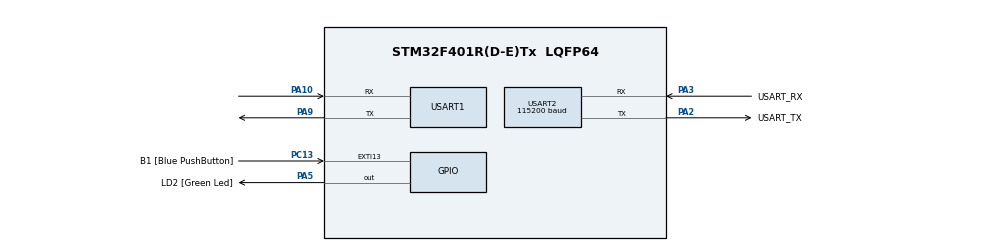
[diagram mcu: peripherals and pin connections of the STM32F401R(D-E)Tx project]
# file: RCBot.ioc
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Mcu.Family=STM32F4
Mcu.Name=STM32F401R(D-E)Tx
Mcu.Package=LQFP64
NVIC.PriorityGroup=NVIC_PRIORITYGROUP_0
PA10.Mode=Asynchronous
PA10.Signal=USART1_RX
PA13.GPIO_Label=TMS
PA13.Mode=Serial_Wire
PA13.Signal=SYS_JTMS-SWDIO
PA14.GPIO_Label=TCK
PA14.Mode=Serial_Wire
PA14.Signal=SYS_JTCK-SWCLK
PA2.GPIO_Label=USART_TX
PA2.GPIO_Mode=GPIO_MODE_AF_PP
PA2.GPIO_PuPd=GPIO_NOPULL
PA2.GPIO_Speed=GPIO_SPEED_FREQ_LOW
PA2.Mode=Asynchronous
PA2.Signal=USART2_TX
PA3.GPIO_Label=USART_RX
PA3.GPIO_Mode=GPIO_MODE_AF_PP
PA3.GPIO_PuPd=GPIO_NOPULL
PA3.GPIO_Speed=GPIO_SPEED_FREQ_LOW
PA3.Mode=Asynchronous
PA3.Signal=USART2_RX
PA5.GPIO_Label=LD2 [Green Led]
PA5.GPIO_Mode=GPIO_MODE_OUTPUT_PP
PA5.GPIO_PuPd=GPIO_NOPULL
PA5.GPIO_Speed=GPIO_SPEED_FREQ_LOW
PA5.Signal=GPIO_Output
PA9.Mode=Asynchronous
PA9.Signal=USART1_TX
PB3.GPIO_Label=SWO
PB3.Signal=SYS_JTDO-SWO
PC13-ANTI_TAMP.GPIO_Label=B1 [Blue PushButton]
PC13-ANTI_TAMP.GPIO_ModeDefaultEXTI=GPIO_MODE_IT_FALLING
PC13-ANTI_TAMP.GPIO_PuPd=GPIO_NOPULL
PC13-ANTI_TAMP.Signal=GPXTI13
PC14-OSC32_IN.Mode=LSE-External-Oscillator
PC14-OSC32_IN.Signal=RCC_OSC32_IN
PC15-OSC32_OUT.Mode=LSE-External-Oscillator
PC15-OSC32_OUT.Signal=RCC_OSC32_OUT
PH0\ -\ OSC_IN.Mode=HSE-External-Clock-Source
PH0\ -\ OSC_IN.Signal=RCC_OSC_IN
PH1\ -\ OSC_OUT.Mode=HSE-External-Clock-Source
PH1\ -\ OSC_OUT.Signal=RCC_OSC_OUT
ProjectManager.HeapSize=0x200
ProjectManager.StackSize=0x400
ProjectManager.TargetToolchain=STM32CubeIDE
RCC.48MHZClocksFreq_Value=48000000
RCC.AHBFreq_Value=84000000
RCC.APB1CLKDivider=RCC_HCLK_DIV2
RCC.APB1Freq_Value=42000000
RCC.APB1TimFreq_Value=84000000
RCC.APB2Freq_Value=84000000
RCC.APB2TimFreq_Value=84000000
RCC.CortexFreq_Value=84000000
RCC.HCLKFreq_Value=84000000
RCC.HSE_VALUE=8000000
RCC.HSI_VALUE=16000000
RCC.PLLN=336
RCC.PLLP=RCC_PLLP_DIV4
RCC.PLLQ=7
RCC.SYSCLKFreq_VALUE=84000000
RCC.SYSCLKSource=RCC_SYSCLKSOURCE_PLLCLK
RCC.VCOOutputFreq_Value=336000000
USART1.VirtualMode=VM_ASYNC
USART2.BaudRate=115200
USART2.VirtualMode=VM_ASYNC
board=NUCLEO-F401RE

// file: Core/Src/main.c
/* USER CODE BEGIN Header */
/**
  ******************************************************************************
  * @file           : main.c
  * @brief          : Main program body
  ******************************************************************************
  */
/* USER CODE END Header */
#include "main.h"
#include <string.h>
#include <stdio.h>

/* USER CODE BEGIN PD */
#define UART_TIMEOUT 1000    // Timeout for LoRa
#define MESSAGE_LENGTH 18    // Length of "Hello from STM32!\r\n"
#define TX_INTERVAL 2000     // 2 seconds between transmissions
#define DEBUG_UART huart2    // Use UART2 for debug messages
/* USER CODE END PD */

UART_HandleTypeDef huart1;
UART_HandleTypeDef huart2;

/* USER CODE BEGIN PV */
uint8_t tx_buffer[] = "Hello from STM32!\r\n";
uint8_t rx_buffer[MESSAGE_LENGTH];
uint32_t last_tx_time = 0;
uint32_t rx_count = 0;
uint32_t tx_count = 0;
uint8_t is_tx_turn = 1;  // Start in TX mode
/* USER CODE END PV */

void SystemClock_Config(void);
static void MX_GPIO_Init(void);
static void MX_USART1_UART_Init(void);
static void MX_USART2_UART_Init(void);

/* USER CODE BEGIN 0 */
void debug_print(const char* msg)
{
    HAL_UART_Transmit(&DEBUG_UART, (uint8_t*)msg, strlen(msg), 100);
}
/* USER CODE END 0 */

int main(void)
{

  /* MCU Configuration--------------------------------------------------------*/

  /* Reset of all peripherals, Initializes the Flash interface and the Systick. */
  HAL_Init();

  /* Configure the system clock */
  SystemClock_Config();

  /* Initialize all configured peripherals */
  MX_GPIO_Init();
  MX_USART1_UART_Init();
  MX_USART2_UART_Init();

  /* USER CODE BEGIN 2 */
  // Initialize LED to OFF state
  HAL_GPIO_WritePin(GPIOA, GPIO_PIN_5, GPIO_PIN_RESET);

  // Store initial time
  last_tx_time = HAL_GetTick();
  /* USER CODE END 2 */

  /* Infinite loop */
  /* USER CODE BEGIN WHILE */
  while (1)
  {
      // Just transmit letter 'A' every second
      uint8_t
{

  huart1.Instance = USART1;
  huart1.Init.BaudRate = 115200;
  huart1.Init.WordLength = UART_WORDLENGTH_8B;
  huart1.Init.StopBits = UART_STOPBITS_1;
  huart1.Init.Parity = UART_PARITY_NONE;
  huart1.Init.Mode = UART_MODE_TX_RX;
  huart1.Init.HwFlowCtl = UART_HWCONTROL_NONE;
  huart1.Init.OverSampling = UART_OVERSAMPLING_16;
  if (HAL_UART_Init(&huart1) != HAL_OK)
  {
    Error_Handler();
  }
}

static void MX_USART2_UART_Init(void)
{

  huart2.Instance = USART2;
  huart2.Init.BaudRate = 115200;
  huart2.Init.WordLength = UART_WORDLENGTH_8B;
  huart2.Init.StopBits = UART_STOPBITS_1;
  huart2.Init.Parity = UART_PARITY_NONE;
  huart2.Init.Mode =

  /*Configure GPIO pin Output Level */
  HAL_GPIO_WritePin(GPIOA, GPIO_PIN_5, GPIO_PIN_RESET);

  /*Configure GPIO pin Output Level */
  HAL_GPIO_WritePin(GPIOB, GPIO_PIN_8, GPIO_PIN_RESET);

  /*Configure GPIO_NOPULL;
  GPIO_InitStruct.Speed = GPIO_SPEED_FREQ_LOW;
  HAL_GPIO_Init(GPIOA, &GPIO_InitStruct);

  /*Configure GPIO pin : PB8 */
  GPIO_InitStruct.Pin = GPIO_PIN_8;
  GPIO_InitStruct.Mode = GPIO_MODE_OUTPUT_PP;
  GPIO_InitStruct.Pull = GPIO_NOPULL;
  GPIO_InitStruct.Speed = GPIO_SPEED_FREQ_LOW;
  HAL_GPIO_Init(GPIOB, &GPIO_InitStruct);

}

void Error_Handler(void)
{
  __disable_irq();
  while (1)
  {
  }
}
